# R7FA2A1AB register map
Vendor: Renesas; Series: RA2; File version: 1.1
CPU: CM23 r1p0, little endian, MPU, no FPU, VTOR, 2 interrupt priority bits
Registers are 8-bit, read-write, reset 0x0 unless marked. A register's access mark holds for its fields unless they carry their own. Offsets are from the block's base; [hi:lo] are bit positions.

## DTC — Data Transfer Controller
Base 0x40005400
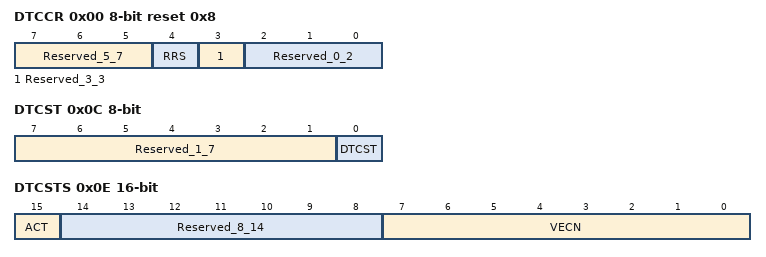
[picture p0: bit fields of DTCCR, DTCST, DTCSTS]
0x00 DTCCR reset 0x8 — DTC Control Register
  [7:5] Reserved_5_7 — These bits are read as 000. The write value should be 000.
  [4] RRS — DTC Transfer Information Read Skip Enable.
  [3] Reserved_3_3 — This bit is read as 1. The write value should be 1.
  [2:0] Reserved_0_2 — These bits are read as 000. The write value should be 000.
0x04 DTCVBR 32-bit — DTC Vector Base Register
  [31:0] DTCVBR — DTC Vector Base Address.Note: A value cannot be set in the lower,order 10 bits. These bits are fixed to 0.
0x0C DTCST — DTC Module Start Register
  [7:1] Reserved_1_7 — These bits are read as 0000000. The write value should be 0000000.
  [0] DTCST — DTC Module Start
0x0E DTCSTS 16-bit ro — DTC Status Register
  [15] ACT — DTC Active Flag
  [14:8] Reserved_8_14 — These bits are read as 0000000.
  [7:0] VECN — DTC,Activating Vector Number MonitoringThese bits indicate the vector number for the activating source when DTC transfer is in progress.The value is only valid if DTC transfer is in progress (the value of the ACT flag is 1)

## MSTP — Module Stop Control B,C,D
Base 0x40047000
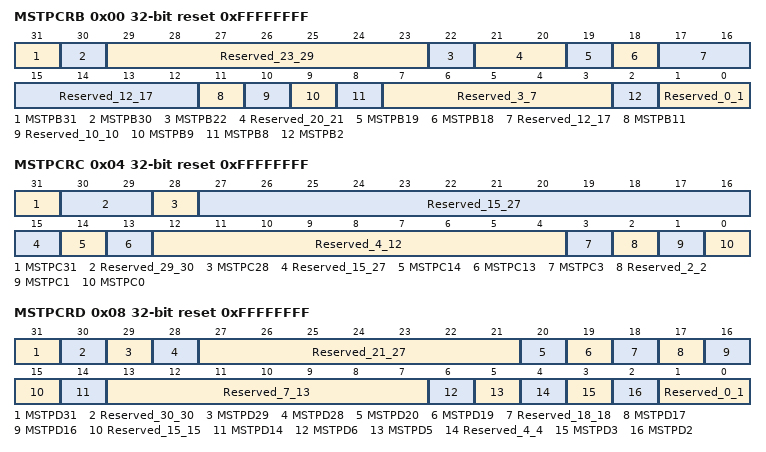
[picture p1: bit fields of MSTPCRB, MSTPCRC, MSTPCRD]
0x00 MSTPCRB 32-bit reset 0xFFFFFFFF — Module Stop Control Register B
  [31] MSTPB31 — Serial Communication Interface 0 Module Stop
  [30] MSTPB30 — Serial Communication Interface 1 Module Stop
  [29:23] Reserved_23_29 — These bits are read as 1111111. The write value should be 1111111.
  [22] MSTPB22 — Serial Communication Interface 9 Module Stop
  [21:20] Reserved_20_21 — These bits are read as 11. The write value should be 11.
  [19] MSTPB19 — Serial Peripheral Interface 0 Module Stop
  [18] MSTPB18 — Serial Peripheral Interface 1 Module Stop
  [17:12] Reserved_12_17 — These bits are read as 111111. The write value should be 111111.
  [11] MSTPB11 — Universal Serial Bus 2.0 FS Interface Module Stop
  [10] Reserved_10_10 — This bit is read as 1. The write value should be 1.
  [9] MSTPB9 — I2C Bus Interface 0 Module Stop
  [8] MSTPB8 — I2C Bus Interface 1 Module Stop
  [7:3] Reserved_3_7 — These bits are read as 11111. The write value should be 11111.
  [2] MSTPB2 — CAN0 Module Stop
  [1:0] Reserved_0_1 — These bits are read as 11. The write value should be 11.
0x04 MSTPCRC 32-bit reset 0xFFFFFFFF — Module Stop Control Register C
  [31] MSTPC31 — AES Module Stop
  [30:29] Reserved_29_30 — These bits are read as 11. The write value should be 11.
  [28] MSTPC28 — Random Number Generator Module Stop
  [27:15] Reserved_15_27 — These bits are read as 1111111111111. The write value should be 1111111111111.
  [14] MSTPC14 — Event Link Controller Module Stop
  [13] MSTPC13 — Data Operation Circuit Module Stop
  [12:4] Reserved_4_12 — These bits are read as 111111111. The write value should be 111111111.
  [3] MSTPC3 — Capacitive Touch Sensing Unit Module Stop
  [2] Reserved_2_2 — This bit is read as 1. The write value should be 1.
  [1] MSTPC1 — CRC Calculator Module Stop
  [0] MSTPC0 — CAC Module Stop
0x08 MSTPCRD 32-bit reset 0xFFFFFFFF — Module Stop Control Register D
  [31] MSTPD31 — Operational Amplifier Module Stop
  [30] Reserved_30_30 — This bit is read as 1. The write value should be 1.
  [29] MSTPD29 — Comparator,LP Module Stop
  [28] MSTPD28 — ACMPHS0 Module Stop
  [27:21] Reserved_21_27 — These bits are read as 1111111. The write value should be 1111111.
  [20] MSTPD20 — 12-bit D/A Converter Module Stop
  [19] MSTPD19 — 8-Bit D/A Converter Module Stop
  [18] Reserved_18_18 — This bit is read as 1. The write value should be 1.
  [17] MSTPD17 — 24-bit Sigma,Delta A/DConverter Module Stop
  [16] MSTPD16 — 16-Bit A/D Converter Module Stop
  [15] Reserved_15_15 — This bit is read as 1. The write value should be 1.
  [14] MSTPD14 — POEG Module Stop
  [13:7] Reserved_7_13 — These bits are read as 1111111. The write value should be 1111111.
  [6] MSTPD6 — GPT ch6 - ch1 Module Stop
  [5] MSTPD5 — GPT ch0 Module Stop
  [4] Reserved_4_4 — This bit is read as 1. The write value should be 1.
  [3] MSTPD3 — AGT0 Module StopNote: AGT0 is in the module stop state when the count source is either of PCLKB, PCLKB/2 or PCLKB/8. In case the count source is sub,clock or LOCO, this bit should be set to 1 except when accessing the registers of AGT0.
  [2] MSTPD2 — AGT1 Module StopNote: AGT1 is in the module stop state when the count source is either of PCLKB, PCLKB/2 or PCLKB/8. In case the count source is sub,clock or LOCO, this bit should be set to 1 except when accessing the registers of AGT1.
  [1:0] Reserved_0_1 — These bits are read as 11. The write value should be 11.
